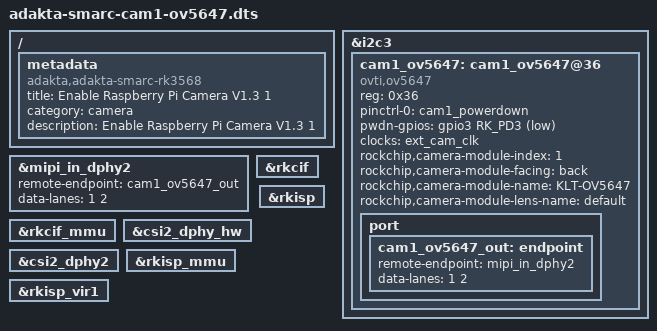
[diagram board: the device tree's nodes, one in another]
/dts-v1/;
/plugin/;

#include <dt-bindings/clock/rk3568-cru.h>
#include <dt-bindings/power/rk3568-power.h>
#include <dt-bindings/gpio/gpio.h>
#include <dt-bindings/pinctrl/rockchip.h>

/ {
	metadata {
		title = "Enable Raspberry Pi Camera V1.3 1";
		compatible = "adakta,adakta-smarc-rk3568";
		category = "camera";
		description = "Enable Raspberry Pi Camera V1.3 1";
	};

	fragment@0 {
		target = <&i2c3>;

		__overlay__ {
			status = "okay";

			cam1_ov5647: cam1_ov5647@36 {
				status = "okay";

				compatible = "ovti,ov5647";
				reg = <0x36>;

				pinctrl-names = "default";
				pinctrl-0 = <&cam1_powerdown>;

				pwdn-gpios = <&gpio3 RK_PD3 GPIO_ACTIVE_LOW>;

				clocks = <&ext_cam_clk>;
				clock-names = "xvclk";

				rockchip,camera-module-index = <1>;
				rockchip,camera-module-facing = "back";
				rockchip,camera-module-name = "KLT-OV5647";
				rockchip,camera-module-lens-name = "default";

				port {
					cam1_ov5647_out: endpoint {
						remote-endpoint = <&mipi_in_dphy2>;
						data-lanes = <1 2>;
					};
				};
			};
		};
	};

	fragment@1 {
		target = <&mipi_in_dphy2>;

		__overlay__ {
			remote-endpoint = <&cam1_ov5647_out>;
			data-lanes = <1 2>;
		};
	};

	fragment@2 {
		target = <&rkcif>;

		__overlay__ {
			status = "okay";
		};
	};

	fragment@3 {
		target = <&rkcif_mmu>;

		__overlay__ {
			status = "okay";
		};
	};

	fragment@4 {
		target = <&csi2_dphy_hw>;

		__overlay__ {
			status = "okay";
		};
	};

	fragment@5 {
		target = <&csi2_dphy2>;

		__overlay__ {
			status = "okay";
		};
	};

	fragment@6 {
		target = <&rkisp>;

		__overlay__ {
			status = "okay";
		};
	};

	fragment@7 {
		target = <&rkisp_mmu>;

		__overlay__ {
			status = "okay";
		};
	};

	fragment@8 {
		target = <&rkisp_vir1>;

		__overlay__ {
			status = "okay";
		};
	};
};
